# STM32F779 register map
File version: 1.8
CPU: CM7 r0p1, little endian, MPU, FPU, 4 interrupt priority bits
Registers are 32-bit, read-write, reset 0x0 unless marked. A register's access mark holds for its fields unless they carry their own. Offsets are from the block's base; [hi:lo] are bit positions; {n}, {i} and the like mark numbered series.

## SPDIFRX — Receiver Interface
Base 0x40004000
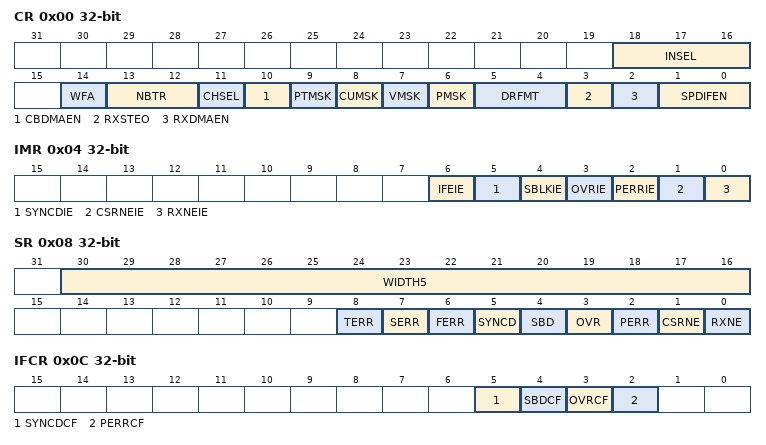
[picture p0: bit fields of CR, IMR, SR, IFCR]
0x00 CR — Control register
  [18:16] INSEL — input selection
  [14] WFA — Wait For Activity
  [13:12] NBTR — Maximum allowed re-tries during synchronization phase
  [11] CHSEL — Channel Selection
  [10] CBDMAEN — Control Buffer DMA ENable for control flow
  [9] PTMSK — Mask of Preamble Type bits
  [8] CUMSK — Mask of channel status and user bits
  [7] VMSK — Mask of Validity bit
  [6] PMSK — Mask Parity error bit
  [5:4] DRFMT — RX Data format
  [3] RXSTEO — STerEO Mode
  [2] RXDMAEN — Receiver DMA ENable for data flow
  [1:0] SPDIFEN — Peripheral Block Enable
0x04 IMR — Interrupt mask register
  [6] IFEIE — Serial Interface Error Interrupt Enable
  [5] SYNCDIE — Synchronization Done
  [4] SBLKIE — Synchronization Block Detected Interrupt Enable
  [3] OVRIE — Overrun error Interrupt Enable
  [2] PERRIE — Parity error interrupt enable
  [1] CSRNEIE — Control Buffer Ready Interrupt Enable
  [0] RXNEIE — RXNE interrupt enable
0x08 SR ro — Status register
  [30:16] WIDTH5 — Duration of 5 symbols counted with SPDIF_CLK
  [8] TERR — Time-out error
  [7] SERR — Synchronization error
  [6] FERR — Framing error
  [5] SYNCD — Synchronization Done
  [4] SBD — Synchronization Block Detected
  [3] OVR — Overrun error
  [2] PERR — Parity error
  [1] CSRNE — Control Buffer register is not empty
  [0] RXNE — Read data register not empty
0x0C IFCR wo — Interrupt Flag Clear register
  [5] SYNCDCF — Clears the Synchronization Done flag
  [4] SBDCF — Clears the Synchronization Block Detected flag
  [3] OVRCF — Clears the Overrun error flag
  [2] PERRCF — Clears the Parity error flag
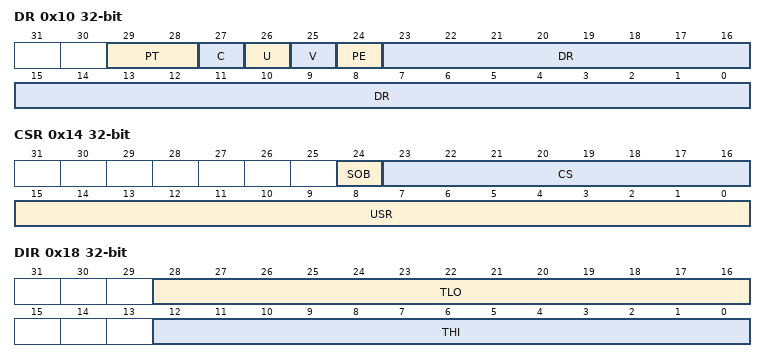
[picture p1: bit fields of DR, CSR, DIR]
0x10 DR ro — Data input register
  [29:28] PT — Preamble Type
  [27] C — Channel Status bit
  [26] U — User bit
  [25] V — Validity bit
  [24] PE — Parity Error bit
  [23:0] DR — Parity Error bit
0x14 CSR ro — Channel Status register
  [24] SOB — Start Of Block
  [23:16] CS — Channel A status information
  [15:0] USR — User data information
0x18 DIR ro — Debug Information register
  [28:16] TLO — Threshold LOW
  [12:0] THI — Threshold HIGH

## MDIOS — Management data input/output slave
Base 0x40017800
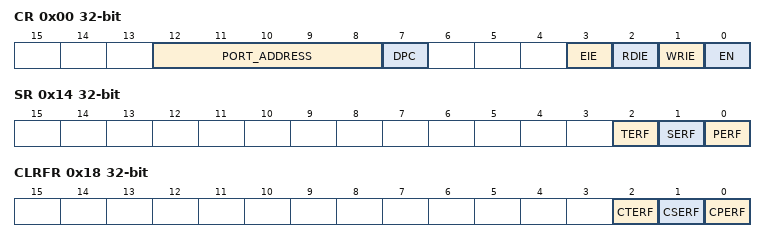
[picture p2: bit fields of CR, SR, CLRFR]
0x00 CR — MDIOS configuration register
  [12:8] PORT_ADDRESS — Slaves's address
  [7] DPC — Disable Preamble Check
  [3] EIE — Error interrupt enable
  [2] RDIE — Register Read Interrupt Enable
  [1] WRIE — Register write interrupt enable
  [0] EN — Peripheral enable
0x04 WRFR ro — MDIOS write flag register
  [31:0] WRF — Write flags for MDIO registers 0 to 31
0x08 CWRFR — MDIOS clear write flag register
  [31:0] CWRF — Clear the write flag
0x0C RDFR ro — MDIOS read flag register
  [31:0] RDF — Read flags for MDIO registers 0 to 31
0x10 CRDFR — MDIOS clear read flag register
  [31:0] CRDF — Clear the read flag
0x14 SR ro — MDIOS status register
  [2] TERF — Turnaround error flag
  [1] SERF — Start error flag
  [0] PERF — Preamble error flag
0x18 CLRFR — MDIOS clear flag register
  [2] CTERF — Clear the turnaround error flag
  [1] CSERF — Clear the start error flag
  [0] CPERF — Clear the preamble error flag
{0x1C+4i} DINR{i} (i=0..31) ro — MDIOS input data register {i}
  [15:0] DIN — Input data received from MDIO Master during write frames
{0x9C+4i} DOUTR{i} (i=0..31) — MDIOS output data register {i}
  [15:0] DOUT — Output data sent to MDIO Master during read frames

## JPEG — JPEG codec
Base 0x50051000
0x00 CONFR0 wo — JPEG codec configuration register 0
  [0] START
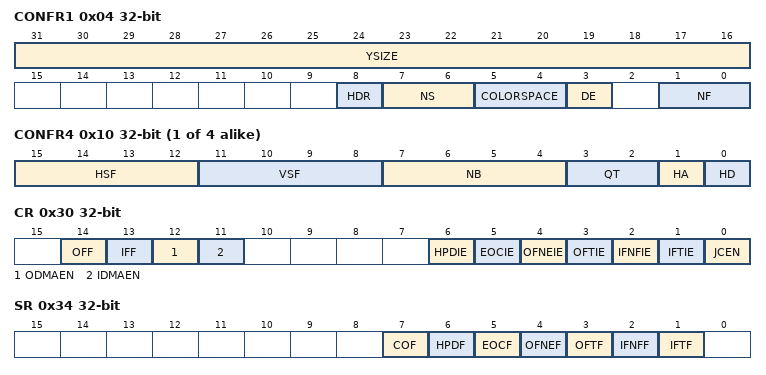
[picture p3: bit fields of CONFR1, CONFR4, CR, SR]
0x04 CONFR1 — JPEG codec configuration register 1
  [31:16] YSIZE
  [8] HDR — Header Processing
  [7:6] NS — Number of components for Scan
  [5:4] COLORSPACE
  [3] DE — Decoding Enable
  [1:0] NF — Number of color components
0x08 CONFR2 — JPEG codec configuration register 2
  [25:0] NMCU — Number of MCU
0x0C CONFR3 — JPEG codec configuration register 3
  [31:16] XSIZE
{0x0+4i} CONFR{i} (i=4..7) — JPEG codec configuration register {i}
  [15:12] HSF — Horizontal Sampling Factor
  [11:8] VSF — Vertical Sampling Factor
  [7:4] NB — Number of Block
  [3:2] QT — Quantization Table
  [1] HA — Huffman AC
  [0] HD — Huffman DC
0x30 CR access per field — JPEG control register
  [14] OFF ro — Output FIFO Flush
  [13] IFF ro — Input FIFO Flush
  [12] ODMAEN rw — Output DMA Enable
  [11] IDMAEN rw — Input DMA Enable
  [6] HPDIE rw — Header Parsing Done Interrupt Enable
  [5] EOCIE rw — End of Conversion Interrupt Enable
  [4] OFNEIE rw — Output FIFO Not Empty Interrupt Enable
  [3] OFTIE rw — Output FIFO Threshold Interrupt Enable
  [2] IFNFIE rw — Input FIFO Not Full Interrupt Enable
  [1] IFTIE rw — Input FIFO Threshold Interrupt Enable
  [0] JCEN rw — JPEG Core Enable
0x34 SR ro — JPEG status register
  [7] COF — Codec Operation Flag
  [6] HPDF — Header Parsing Done Flag
  [5] EOCF — End of Conversion Flag
  [4] OFNEF — Output FIFO Not Empty Flag
  [3] OFTF — Output FIFO Threshold Flag
  [2] IFNFF — Input FIFO Not Full Flag
  [1] IFTF — Input FIFO Threshold Flag
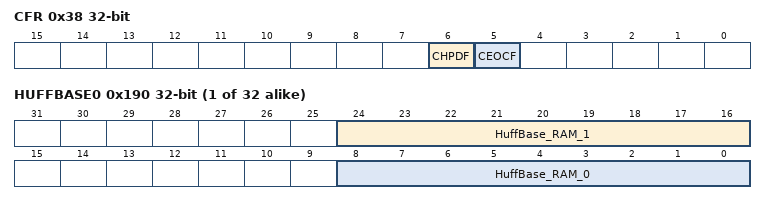
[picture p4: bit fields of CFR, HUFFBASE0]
0x38 CFR wo — JPEG clear flag register
  [6] CHPDF — Clear Header Parsing Done Flag
  [5] CEOCF — Clear End of Conversion Flag
0x40 DIR wo — JPEG data input register
  [31:0] DATAIN — Data Input FIFO
0x44 DOR ro — JPEG data output register
  [31:0] DATAOUT — Data Output FIFO
{0x50+4i} QMEM0{i} (i=0..15) — JPEG quantization tables
  [31:0] QMem_RAM
{0x90+4i} QMEM1{i} (i=0..15) — JPEG quantization tables
  [31:0] QMem_RAM
{0xD0+4i} QMEM2{i} (i=0..15) — JPEG quantization tables
  [31:0] QMem_RAM
{0x110+4i} QMEM3{i} (i=0..15) — JPEG quantization tables
  [31:0] QMem_RAM
{0x150+4i} HUFFMIN{i} (i=0..15) — JPEG HuffMin tables
  [31:0] HuffMin_RAM
{0x190+4i} HUFFBASE{i} (i=0..31) — JPEG HuffSymb tables
  [24:16] HuffBase_RAM_1 — HuffBase RAM
  [8:0] HuffBase_RAM_0 — HuffBase RAM
{0x210+4i} HUFFSYMB{i} (i=0..83) — JPEG HUFFSYMB tables
  [31:0] HuffSymb_RAM — DHTSymb RAM
0x360 DHTMEM{x} (x=0,2,3,4,5,6,7,8,9,10,11,12,13,14,15,16,17,18,19,20,21,22,23,24,25,26,27,28,29,30,31,32,33,34,35,36,37,38,39,40,41,42,43,44,45,46,47,48,49,50,51,52,53,54,55,56,57,58,59,60,61,62,63,64,65,66,67,68,69,70,71,72,73,74,75,76,77,78,79,80,81,82,83,84,85,86,87,88,89,90,91,92,93,94,95,96,97,98,99,100,101,102,103; step 0x4) — JPEG DHTMem tables
  [31:0] DHTMem_RAM
{0x500+4i} HUFFENC_AC0{i} (i=0..87) — JPEG encoder, AC Huffman table 0
  [31:0] DHTMem_RAM
{0x660+4i} HUFFENC_AC1{i} (i=0..87) — JPEG encoder, AC Huffman table 1
  [31:0] DHTMem_RAM
{0x7C0+4i} HUFFENC_DC0{i} (i=0..7) — JPEG encoder, DC Huffman table 0
  [31:0] DHTMem_RAM
{0x7E0+4i} HUFFENC_DC1{i} (i=0..7) — JPEG encoder, DC Huffman table 1
  [31:0] DHTMem_RAM
